# CY8C5888AXI_LP096 register map
File version: 0.1
CY8C58LP
Registers are 8-bit, read-write, no defined reset value unless marked. A register's access mark holds for its fields unless they carry their own. Offsets are from the block's base; lines under a group give offsets from that group; [hi:lo] are bit positions; {n}, {i} and the like mark numbered series; 'fields as' and 'values as' point back to an identical list; <NAME> marks a mode.

## Memory map
0x00000000 I2C_1
0x00000000 PWM_1
0x00000000 PWM_2
0x00000000 Opamp_2
0x00000000 PGA_1
0x00000000 PGA_2
0x00000000 UART_2 — UART
0x00000000 ADC_SAR_1 — SAR ADC
0x00000000 Timer_1
0x00000000 Timer_2
0x00000000 VDAC8_1
0x00000000 ADC_SAR_2 — SAR ADC
0x00000000 Opamp_1
0x00000000 QuadDec_1
0x00000000 QuadDec_1_Cnt16
0x00000000 ADC_DelSig_1
0x00000000 I2C_0
0x00000000 USBUART_1 — USBFS
0x40006472 T2_RESET
0x40006476 Use_Hall
0x4000647A Coast_Brake
0x4000647B UART_DMA_XMIT
0x40006576 Virtual_Hall
0x40006577 MotorDirection

## I2C_1
Base 0x00000000
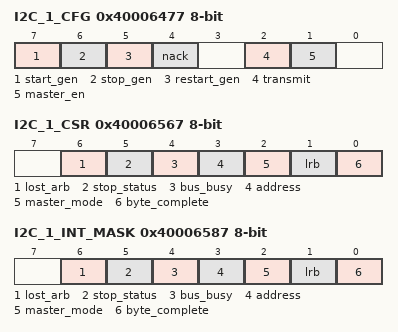
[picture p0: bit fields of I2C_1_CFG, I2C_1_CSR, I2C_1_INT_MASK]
0x40006477 I2C_1_CFG — I2C Configuration Register
  [7] start_gen — Set to 1 to generate a Start condition on the bus. This bit must be cleared by firmware before initiating the next transaction.
  [6] stop_gen — Set to 1 to generate a Stop condition on the bus. This bit must be cleared by firmware before initiating the next transaction.
  [5] restart_gen — Set to 1 to generate a Restart condition on the bus. This bit must be cleared by firmware after a Restart condition is generated.
  [4] nack — Set to 1 to NAK the next read byte. Clear to ACK next read byte. This bit must be cleared by firmware between bytes.
  [2] transmit — Set to 1 to set the current mode to transmit or clear to 0 to receive a byte of data. This bit must be cleared by firmware before starting the next transmit or receive transaction.
  [1] master_en — Set to 1 to enable the master functionality.
0x40006507 I2C_1_DATA — I2C Data Register
  [7:0] data — Read received data or write data to transmit.
0x40006567 I2C_1_CSR — I2C Status Register
  [6] lost_arb ro — If set, indicates arbitration was lost (multi-master and multi-master-slave modes).
  [5] stop_status ro — If set, indicates a Stop condition was detected on the bus.
  [4] bus_busy ro — If set, indicates the bus is busy. Data is currently being transmitted or received.
  [3] address ro — Address detection. If set, indicates that an address byte was sent.
  [2] master_mode ro — Indicates that a valid Start condition was generated and a hardware device is operating as bus master.
  [1] lrb ro — Last Received Bit. Indicates the state of the last received bit, which is the ACK/NAK received for the last byte transmitted. Cleared = ACK and set = NAK.
  [0] byte_complete ro — Transmit or receive status since the last read of this register. In Transmit mode this bit indicates that eight bits of data plus ACK/NAK have been transmitted since the last read. In Receive mode this bit indicates that eight bits of data have been received since the last read of this register.
0x40006587 I2C_1_INT_MASK — I2C Interrupt Enable Mask
  [6] lost_arb — Enables interrupt from the corresponding bit in status register.
  [5] stop_status — Enables interrupt from the corresponding bit in status register.
  [4] bus_busy — Enables interrupt from the corresponding bit in status register.
  [3] address — Enables interrupt from the corresponding bit in status register.
  [2] master_mode — Enables interrupt from the corresponding bit in status register.
  [1] lrb — Enables interrupt from the corresponding bit in status register.
  [0] byte_complete — Enables interrupt from the corresponding bit in status register.

## PWM_1
Base 0x00000000
0x40006409 PWM_1_DeadBand_Counter — UDB DeadBand - DeadBand Counter Value
0x40006429 PWM_1_DeadBand_Count — UDB DeadBand - Assigned DeadBand Count Value
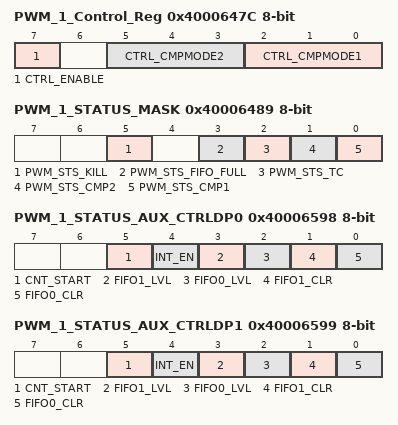
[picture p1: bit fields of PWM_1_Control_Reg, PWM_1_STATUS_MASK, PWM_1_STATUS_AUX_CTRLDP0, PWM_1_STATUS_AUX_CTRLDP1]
0x4000647C PWM_1_Control_Reg — UDB Control Register - Assigned Control Register Value
  [7] CTRL_ENABLE — Enable the PWM
  [5:3] CTRL_CMPMODE2 — Compare mode 2
  [2:0] CTRL_CMPMODE1 — Compare mode 1
0x40006489 PWM_1_STATUS_MASK — UDB Status bits Interrupt Mask Enable Register
  [5] PWM_STS_KILL ro — Enables the Interrupt on Kill
  [3] PWM_STS_FIFO_FULL ro — FIFO Full Status Mask
  [2] PWM_STS_TC ro — Enables the Interrupt on Terminal Count
  [1] PWM_STS_CMP2 ro — Enables the Interrupt on Compare 2
  [0] PWM_STS_CMP1 ro — Enables the Interrupt on Compare 1
0x40006528 PWM_1_COMPARE_1 16-bit — UDB.D0 - Assigned Compare1 Value
0x40006538 PWM_1_COMPARE_2 16-bit — UDB.D1 - Assigned Compare2 Value
0x40006598 PWM_1_STATUS_AUX_CTRLDP0 — UDB Auxilliary Control Register
  [5] CNT_START — FIFO0 clear
    0=E_CNT_START0 (Disable counter); 1=E_CNT_START1 (Enable counter)
  [4] INT_EN
    0=E_INT_EN0 (Interrupt disabled); 1=E_INT_EN1 (Interrupt enabled)
  [3] FIFO1_LVL — FIFO level
    0=E_FIFO_LVL_0 (FIFO LVL: input mode: FIFO not full; output mode: FIFO not empty); 1=E_FIFO_LVL_1 (FIFO LVL: input mode: FIFO at least 1/2 empty; output mode: FIFO at least 1/2 full)
  [2] FIFO0_LVL — FIFO level
    values as FIFO1_LVL
  [1] FIFO1_CLR — FIFO1 clear
    0=E_FIFO_CLR_0 (Normal FIFO operation); 1=E_FIFO_CLR_1 (Clear FIFO state)
  [0] FIFO0_CLR — FIFO0 clear
    values as FIFO1_CLR
0x40006599 PWM_1_STATUS_AUX_CTRLDP1 — UDB Auxilliary Control Register
  fields as PWM_1_STATUS_AUX_CTRLDP0
